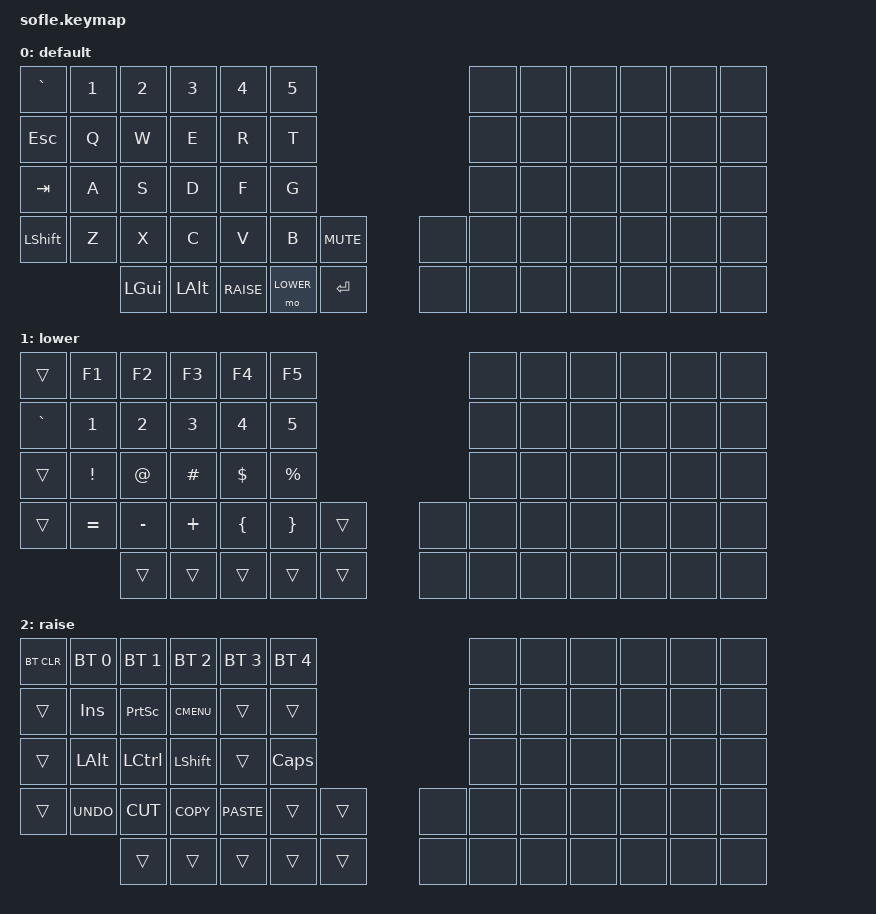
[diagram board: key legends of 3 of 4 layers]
/*
 * Copyright (c) 2020 The ZMK Contributors
 *
 * SPDX-License-Identifier: MIT
 */

#include <behaviors.dtsi>
#include <dt-bindings/zmk/keys.h>
#include <dt-bindings/zmk/bt.h>
#include <dt-bindings/zmk/rgb.h>
#include <dt-bindings/zmk/ext_power.h>

#define BASE 0
#define LOWER 1
#define RAISE 2
#define ADJUST 3

/ {

   // Activate ADJUST layer by pressing raise and lower
    conditional_layers {
        compatible = "zmk,conditional-layers";
        adjust_layer {
            if-layers = <LOWER RAISE>;
            then-layer = <ADJUST>;
        };
    };

    keymap {
        compatible = "zmk,keymap";

        default_layer {
            display-name = "default";
            bindings = <
&kp GRAVE &kp N1 &kp N2   &kp N3   &kp N4    &kp N5                          &none &none &none &none &none &none
&kp ESC   &kp Q  &kp W    &kp E    &kp R     &kp T                           &none &none &none &none &none &none
&kp TAB   &kp A  &kp S    &kp D    &kp F     &kp G                           &none &none &none &none &none &none
&kp LSHFT &kp Z  &kp X    &kp C    &kp V     &kp B      &kp C_MUTE    &none  &none &none &none &none &none &none
                 &kp LGUI &kp LALT &kp RAISE &mo LOWER  &kp RET       &none  &none &none &none &none &none &none
            >;

            sensor-bindings = <&inc_dec_kp C_VOL_UP C_VOL_DN &inc_dec_kp PG_UP PG_DN>;
        };

        lower_layer {
            display-name = "lower";
            bindings = <
&trans    &kp F1    &kp F2    &kp F3      &kp F4    &kp F5                      &none &none &none &none &none &none
&kp GRAVE &kp N1    &kp N2    &kp N3      &kp N4    &kp N5                      &none &none &none &none &none &none
&trans    &kp EXCL  &kp AT    &kp HASH    &kp DLLR  &kp PRCNT                   &none &none &none &none &none &none
&trans    &kp EQUAL &kp MINUS &kp PLUS    &kp LBRC  &kp RBRC   &trans    &none  &none &none &none &none &none &none
                    &trans    &trans      &trans    &trans     &trans    &none  &none &none &none &none &none &none
            >;

            sensor-bindings = <&inc_dec_kp C_VOL_UP C_VOL_DN &inc_dec_kp PG_UP PG_DN>;
        };

        raise_layer {
            display-name = "raise";
            bindings = <
&bt BT_CLR &bt BT_SEL 0 &bt BT_SEL 1 &bt BT_SEL 2 &bt BT_SEL 3 &bt BT_SEL 4                   &none &none &none &none &none &none
&trans     &kp INS      &kp PSCRN    &kp K_CMENU  &trans       &trans                         &none &none &none &none &none &none
&trans     &kp LALT     &kp LCTRL    &kp LSHFT    &trans       &kp CLCK                       &none &none &none &none &none &none
&trans     &kp K_UNDO   &kp K_CUT    &kp K_COPY   &kp K_PASTE  &trans        &trans    &none  &none &none &none &none &none &none
                        &trans       &trans       &trans       &trans        &trans    &none  &none &none &none &none &none &none
            >;

            sensor-bindings = <&inc_dec_kp C_VOL_UP C_VOL_DN &inc_dec_kp PG_UP PG_DN>;
        };

        adjust_layer {
            display-name = "adjust";
            bindings = <
&bt BT_CLR        &bt BT_SEL 0    &bt BT_SEL 1    &bt BT_SEL 2    &bt BT_SEL 3    &bt BT_SEL 4                               &none &none &none &none &none &none
&ext_power EP_TOG &rgb_ug RGB_HUD &rgb_ug RGB_HUI &rgb_ug RGB_SAD &rgb_ug RGB_SAI &rgb_ug RGB_EFF                            &none &none &none &none &none &none
&out OUT_TOG      &rgb_ug RGB_BRD &rgb_ug RGB_BRI &none           &none           &none                                      &none &none &none &none &none &none
&studio_unlock    &none           &none           &none           &none           &none            &rgb_ug RGB_TOG    &none  &none &none &none &none &none &none
                                  &none           &none           &none           &none            &none              &none  &none &none &none &none
            >;
        };

    };
};
